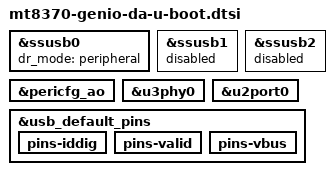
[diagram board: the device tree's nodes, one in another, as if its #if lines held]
// SPDX-License-Identifier: (GPL-2.0-only OR MIT)
/*
 * Copyright (c) 2026 BayLibre, SAS.
 * Author: Carlo Caione <ccaione@baylibre.com>
 */

/*
 * Download agents (DAs) run from RAM to provision or recover eMMC.
 * Both variants expose USB0 as a peripheral and leave unused USB
 * controllers disabled, independently of the normal boot USB setup.
 */

#include "mtk-genio-binman-u-boot.dtsi"
#include "mtk-genio-da-binman-u-boot.dtsi"

&ssusb0 {
	dr_mode = "peripheral";
};

&ssusb1 {
	status = "disabled";
};

&ssusb2 {
	status = "disabled";
};

/* Only the SPL fastboot variant needs these USB dependencies in SPL. */
#ifdef CONFIG_SPL_MTK_BROM_DOWNLOAD_AGENT_FASTBOOT
&pericfg_ao {
	bootph-pre-ram;
};

&ssusb0 {
	bootph-pre-ram;
};

&u3phy0 {
	bootph-pre-ram;
};

&u2port0 {
	bootph-pre-ram;
};

&usb_default_pins {
	bootph-pre-ram;

	pins-iddig {
		bootph-pre-ram;
	};

	pins-valid {
		bootph-pre-ram;
	};

	pins-vbus {
		bootph-pre-ram;
	};
};
#endif
